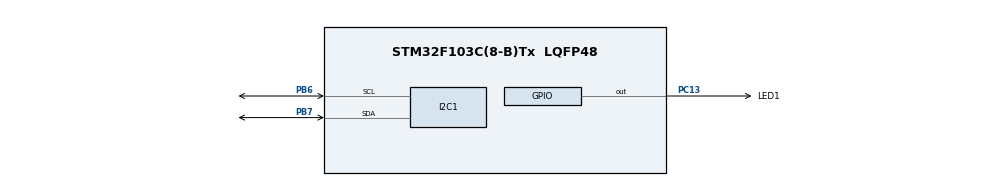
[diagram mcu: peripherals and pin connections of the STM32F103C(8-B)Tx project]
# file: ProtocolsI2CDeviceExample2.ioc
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Mcu.Family=STM32F1
Mcu.Name=STM32F103C(8-B)Tx
Mcu.Package=LQFP48
NVIC.I2C1_ER_IRQn=true\:0\:0\:false\:false\:true\:true\:true\:true
NVIC.I2C1_EV_IRQn=true\:0\:0\:false\:false\:true\:true\:true\:true
NVIC.PriorityGroup=NVIC_PRIORITYGROUP_4
PA13.Mode=Serial_Wire
PA13.Signal=SYS_JTMS-SWDIO
PA14.Mode=Serial_Wire
PA14.Signal=SYS_JTCK-SWCLK
PB6.Mode=I2C
PB6.Signal=I2C1_SCL
PB7.Mode=I2C
PB7.Signal=I2C1_SDA
PC13-TAMPER-RTC.GPIO_Label=LED1
PC13-TAMPER-RTC.GPIO_ModeDefaultOutputPP=GPIO_MODE_OUTPUT_PP
PC13-TAMPER-RTC.Signal=GPIO_Output
ProjectManager.HeapSize=0x200
ProjectManager.StackSize=0x400
ProjectManager.TargetToolchain=STM32CubeIDE
RCC.APB1Freq_Value=8000000
RCC.APB2Freq_Value=8000000
board=custom

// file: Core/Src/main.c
/* USER CODE BEGIN Header */
/**
  ******************************************************************************
  * @file           : main.c
  * @brief          : Main program body
  ******************************************************************************
  * @attention
  *
  * Copyright (c) 2022 STMicroelectronics.
  * All rights reserved.
  *
  * This software is licensed under terms that can be found in the LICENSE file
  * in the root directory of this software component.
  * If no LICENSE file comes with this software, it is provided AS-IS.
  *
  ******************************************************************************
  */
/* USER CODE END Header */
#include "main.h"

 I2C_HandleTypeDef hi2c1;

void SystemClock_Config(void);
static void MX_GPIO_Init(void);
static void MX_I2C1_Init(void);
/* USER CODE BEGIN PFP */

uint8_t receive_buffer[3];

/* USER CODE END PFP */

/* USER CODE BEGIN 0 */
void HAL_I2C_SlaveRxCpltCallback(I2C_HandleTypeDef *hi2c1){
	// we received 3 bytes of data!

	/* We have only 128 kByte of flash, from 3 bytes received, we only need 17 bits.
	 * make sure the upper 7 bits are not set.
	 */
	if(!(receive_buffer[0] && 0xFE)){
			// we have a valid address
			uint32_t received_address = 0x00000000 | (receive_buffer[0] << 16);
			received_address = received_address | (receive_buffer[1] << 8);
			received_address = received_address | (receive_buffer[2]);

			hi2c1->current_address = (uint8_t *) (FLASH_BASE + received_address);
	}

	  HAL_GPIO_TogglePin(LED1_GPIO_Port, LED1_Pin);
}

void HAL_I2C_AddrCallback(I2C_HandleTypeDef *hi2c1, uint8_t TransferDirection, uint16_t AddrMatchCode){
	  if(TransferDirection == I2C_DIRECTION_RECEIVE){
		  // doing_trasmit will be reset in the HAL_I2C_ErrorCallback.
		  // The controller will stop receiving bytes by sending a NACK. This will result in a Error and
		  // subsequently into a callback to HAL_I2C_ErrorCallback
		  HAL_I2C_Slave_Seq_Transmit_IT(hi2c1, hi2c1->current_address, (uint16_t)0xFFFFF, I2C_FIRST_FRAME);
	  }

	  if(TransferDirection == I2C_DIRECTION_TRANSMIT){
		  HAL_I2C_Slave_Seq_Receive_IT(hi2c1, receive_buffer, 3, I2C_FIRST_AND_LAST_FRAME);
	  }
}

void HAL_I2C_ErrorCallback(I2C_HandleTypeDef *hi2c){
	// This is a hack. The current_address pointer is always shifted one byte too far.
	// If the error was HAL_I2C_ERROR_AF (ACK Failed), we substract one to correct that.
	if(hi2c->ErrorCode == HAL_I2C_ERROR_AF)
		hi2c->current_address--;
}
/* USER CODE END 0 */

int main(void)
{

  /* MCU Configuration--------------------------------------------------------*/

  /* Reset of all peripherals, Initializes the Flash interface and the Systick. */
  HAL_Init();

  /* Configure the system clock */
  SystemClock_Config();

  /* Initialize all configured peripherals */
  MX_GPIO_Init();
  MX_I2C1_Init();
  /* USER CODE BEGIN 2 */
  hi2c1.current_address = (uint8_t *) FLASH_BASE;
  /* USER CODE END 2 */

  /* Infinite loop */
  /* USER CODE BEGIN WHILE */
  while (1){

	  while(HAL_I2C_GetState(&hi2c1) != HAL_I2C_STATE_READY){
		  HAL_Delay(500);
	  }

	  while (HAL_I2C_EnableListen_IT(&hi2c1) != HAL_OK){
		  HAL_Delay(100);
	  }
  }
  /* USER CODE END 3 */
}

void SystemClock_Config(void)
{
  RCC_OscInitTypeDef RCC_OscInitStruct = {0};
  RCC_ClkInitTypeDef RCC_ClkInitStruct = {0};

  /** Initializes the RCC Oscillators according to the specified parameters
  * in the RCC_OscInitTypeDef structure.
  */
  RCC_OscInitStruct.OscillatorType = RCC_OSCILLATORTYPE_HSI;
  RCC_OscInitStruct.HSIState = RCC_HSI_ON;
  RCC_OscInitStruct.HSICalibrationValue = RCC_HSICALIBRATION_DEFAULT;
  RCC_OscInitStruct.PLL.PLLState = RCC_PLL_NONE;
  if (HAL_RCC_OscConfig(&RCC_OscInitStruct) != HAL_OK)
  {
    Error_Handler();
  }

  /** Initializes the CPU, AHB and APB buses clocks
  */
  RCC_ClkInitStruct.ClockType = RCC_CLOCKTYPE_HCLK|RCC_CLOCKTYPE_SYSCLK
                              |RCC_CLOCKTYPE_PCLK1|RCC_CLOCKTYPE_PCLK2;
  RCC_ClkInitStruct.SYSCLKSource = RCC_SYSCLKSOURCE_HSI;
  RCC_ClkInitStruct.AHBCLKDivider = RCC_SYSCLK_DIV1;
  RCC_ClkInitStruct.APB1CLKDivider = RCC_HCLK_DIV1;
  RCC_ClkInitStruct.APB2CLKDivider = RCC_HCLK_DIV1;

  if (HAL_RCC_ClockConfig(&RCC_ClkInitStruct, FLASH_LATENCY_0) != HAL_OK)
  {
    Error_Handler();
  }
}

static void MX_I2C1_Init(void)
{

  hi2c1.Instance = I2C1;
  hi2c1.Init.ClockSpeed = 100000;
  hi2c1.Init.DutyCycle = I2C_DUTYCYCLE_2;
  hi2c1.Init.OwnAddress1 = 0x42;
  hi2c1.Init.AddressingMode = I2C_ADDRESSINGMODE_7BIT;
  hi2c1.Init.DualAddressMode = I2C_DUALADDRESS_DISABLE;
  hi2c1.Init.OwnAddress2 = 0;
  hi2c1.Init.GeneralCallMode = I2C_GENERALCALL_DISABLE;
  hi2c1.Init.NoStretchMode = I2C_NOSTRETCH_ENABLE;
  if (HAL_I2C_Init(&hi2c1) != HAL_OK)
  {
    Error_Handler();
  }

}

static void MX_GPIO_Init(void)
{
  GPIO_InitTypeDef GPIO_InitStruct = {0};

  /* GPIO Ports Clock Enable */
  __HAL_RCC_GPIOC_CLK_ENABLE();
  __HAL_RCC_GPIOA_CLK_ENABLE();
  __HAL_RCC_GPIOB_CLK_ENABLE();

  /*Configure GPIO pin Output Level */
  HAL_GPIO_WritePin(LED1_GPIO_Port, LED1_Pin, GPIO_PIN_RESET);

  /*Configure GPIO pin : LED1_Pin */
  GPIO_InitStruct.Pin = LED1_Pin;
  GPIO_InitStruct.Mode = GPIO_MODE_OUTPUT_PP;
  GPIO_InitStruct.Pull = GPIO_NOPULL;
  GPIO_InitStruct.Speed = GPIO_SPEED_FREQ_LOW;
  HAL_GPIO_Init(LED1_GPIO_Port, &GPIO_InitStruct);

}

void Error_Handler(void)
{
  __disable_irq();
  while (1)
  {
  }
}
